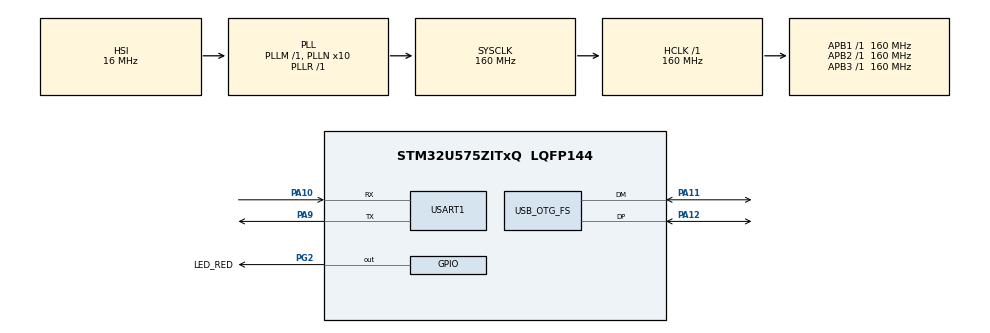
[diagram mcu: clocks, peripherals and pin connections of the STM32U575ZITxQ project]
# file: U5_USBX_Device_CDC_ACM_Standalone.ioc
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CORTEX_M33_NS.userName=CORTEX_M33
GPDMA1.DIRECTION_GPDMACH0=DMA_MEMORY_TO_PERIPH
GPDMA1.IPHANDLE_GPDMACH0-SIMPLEREQUEST_GPDMACH0=__NULL
GPDMA1.REQUEST_GPDMACH0=GPDMA1_REQUEST_USART1_TX
GPDMA1.SRCINC_GPDMACH0=DMA_SINC_INCREMENTED
Mcu.Family=STM32U5
Mcu.Name=STM32U575ZITxQ
Mcu.Package=LQFP144
NVIC.GPDMA1_Channel0_IRQn=true\:0\:0\:false\:false\:true\:false\:true\:true
NVIC.OTG_FS_IRQn=true\:7\:0\:true\:false\:true\:true\:true\:true
NVIC.PriorityGroup=NVIC_PRIORITYGROUP_4
NVIC.USART1_IRQn=true\:6\:0\:true\:false\:true\:false\:true\:true
PA10.GPIO_Speed=GPIO_SPEED_FREQ_HIGH
PA10.Mode=Asynchronous
PA10.Signal=USART1_RX
PA11.GPIO_Speed=GPIO_SPEED_FREQ_HIGH
PA11.Mode=Device_Only
PA11.Signal=USB_OTG_FS_DM
PA12.GPIO_Speed=GPIO_SPEED_FREQ_HIGH
PA12.Mode=Device_Only
PA12.Signal=USB_OTG_FS_DP
PA9.GPIO_Speed=GPIO_SPEED_FREQ_HIGH
PA9.Mode=Asynchronous
PA9.Signal=USART1_TX
PG2.GPIO_Label=LED_RED
PG2.Signal=GPIO_Output
ProjectManager.HeapSize=0x200
ProjectManager.StackSize=0x400
ProjectManager.TargetToolchain=STM32CubeIDE
RCC.ADCFreq_Value=16000000
RCC.AHBFreq_Value=160000000
RCC.APB1Freq_Value=160000000
RCC.APB1TimFreq_Value=160000000
RCC.APB2Freq_Value=160000000
RCC.APB2TimFreq_Value=160000000
RCC.APB3Freq_Value=160000000
RCC.CortexFreq_Value=160000000
RCC.EPOD_VALUE=16000000
RCC.HCLKFreq_Value=160000000
RCC.HSE_VALUE=16000000
RCC.HSI48_VALUE=48000000
RCC.HSI_VALUE=16000000
RCC.LSE_VALUE=32768
RCC.LSIDIV_VALUE=32000
RCC.MSIClockRange=RCC_MSIRANGE_0
RCC.MSI_VALUE=48000000
RCC.PLL1R=1
RCC.PLL2FRACN=0
RCC.PLL3FRACN=0
RCC.PLLFRACN=0
RCC.PLLN=10
RCC.PLLSourceVirtual=RCC_PLLSOURCE_HSI
RCC.SYSCLKFreq_VALUE=160000000
RCC.SYSCLKSource=RCC_SYSCLKSOURCE_PLLCLK
RCC.USBFreq_Value=48000000
RCC.VCOOutputFreq_Value=160000000
USART1.VirtualMode-Asynchronous=VM_ASYNC
USBX.BSP.number=1
USBX.Core_System=1
USBX.USBD_CDCACM_EPINCMD_ADDR=2
USBX.USBD_CDCACM_EPIN_ADDR=1
USBX.USBX_DEVICE_SYS_SIZE=4*1024
USBX.UX_DEVICE_APP_MEM_POOL_SIZE_STANDALONE=1024*8
USBX.UX_DEVICE_CDC_ACM=1
USBX.UX_DEVICE_CLASS_CDC_ACM_TRANSMISSION_DISABLE=1
USBX.UX_Device_Controller=1
USBX.UX_Device_CoreStack=1
USBX.UX_SLAVE_REQUEST_DATA_MAX_LENGTH=512
USBX0.BSP.STBoard=false
USBX0.BSP.api=Unknown
USBX0.BSP.condition=SEMAOoUSBOoOTGOoFSOoDEVICEOoFOROoUSBX & \!DIE455
USBX0.BSP.instance=USB_OTG_FS
USBX0.BSP.ip=USB_OTG_FS
USBX0.BSP.mode=Device_Only
USBX0.BSP.name=USBDevice
USBX0.BSP.solution=USB_OTG_FS
USB_OTG_FS.VirtualMode=Device_Only
VP_GPDMA1_VS_GPDMACH0.Mode=SIMPLEREQUEST_GPDMACH0
VP_ICACHE_VS_ICACHE.Mode=DirectMappedCache
VP_LPBAMQUEUE_VS_QUEUE.Mode=QUEUEMODE
VP_LPBAM_VS_SIG1.Mode=SmartRun
VP_LPBAM_VS_SIG4.Mode=LPDMA1
VP_MEMORYMAP_VS_MEMORYMAP.Mode=CurAppReg
VP_PWR_VS_SECSignals.Mode=Security/Privilege
VP_RCC_USB.Mode=CRS SYNC Source USB
VP_USBX_Core_System.Mode=Core_System
VP_USBX_UX\ Device\ CDC\ ACM\ Class_FS.Mode=UX_Device_class_CDC_ACM_FS
VP_USBX_UX\ Device\ Controller_FS.Mode=UX_Device_Controller_FS
VP_USBX_UX\ Device\ CoreStack_FS.Mode=UX_Device_CoreStack_FS
board=custom

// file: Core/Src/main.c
/* USER CODE BEGIN Header */
/**
  ******************************************************************************
  * @file           : main.c
  * @brief          : Main program body
  ******************************************************************************
  * @attention
  *
  * Copyright (c) 2024 STMicroelectronics.
  * All rights reserved.
  *
  * This software is licensed under terms that can be found in the LICENSE file
  * in the root directory of this software component.
  * If no LICENSE file comes with this software, it is provided AS-IS.
  *
  ******************************************************************************
  */
/* USER CODE END Header */
#include "main.h"
#include "app_usbx_device.h"

UART_HandleTypeDef huart1;
DMA_HandleTypeDef handle_GPDMA1_Channel0;

PCD_HandleTypeDef hpcd_USB_OTG_FS;

void SystemClock_Config(void);
static void MX_GPIO_Init(void);
static void MX_GPDMA1_Init(void);
static void MX_ICACHE_Init(void);
static void MX_USART1_UART_Init(void);
static void MX_USB_OTG_FS_PCD_Init(void);

int main(void)
{

  /* MCU Configuration--------------------------------------------------------*/

  /* Reset of all peripherals, Initializes the Flash interface and the Systick. */
  HAL_Init();

  /* Configure the system clock */
  SystemClock_Config();

  /* Initialize all configured peripherals */
  MX_GPIO_Init();
  MX_GPDMA1_Init();
  MX_ICACHE_Init();
  MX_USART1_UART_Init();
  MX_USB_OTG_FS_PCD_Init();
  MX_USBX_Device_Init();

  /* Infinite loop */
  /* USER CODE BEGIN WHILE */
  while (1)
  {
	  MX_USBX_Device_Process();
    /* USER CODE END WHILE */

  }
}

void SystemClock_Config(void)
{
  RCC_OscInitTypeDef RCC_OscInitStruct = {0};
  RCC_ClkInitTypeDef RCC_ClkInitStruct = {0};
  RCC_CRSInitTypeDef RCC_CRSInitStruct = {0};

  /** Configure the main internal regulator output voltage
  */
  if (HAL_PWREx_ControlVoltageScaling(PWR_REGULATOR_VOLTAGE_SCALE1) != HAL_OK)
  {
    Error_Handler();
  }

  /** Initializes the CPU, AHB and APB buses clocks
  */
  RCC_OscInitStruct.OscillatorType = RCC_OSCILLATORTYPE_HSI48|RCC_OSCILLATORTYPE_HSI;
  RCC_OscInitStruct.HSIState = RCC_HSI_ON;
  RCC_OscInitStruct.HSI48State = RCC_HSI48_ON;
  RCC_OscInitStruct.HSICalibrationValue = RCC_HSICALIBRATION_DEFAULT;
  RCC_OscInitStruct.PLL.PLLState = RCC_PLL_ON;
  RCC_OscInitStruct.PLL.PLLSource = RCC_PLLSOURCE_HSI;
  RCC_OscInitStruct.PLL.PLLMBOOST = RCC_PLLMBOOST_DIV1;
  RCC_OscInitStruct.PLL.PLLM = 1;
  RCC_OscInitStruct.PLL.PLLN = 10;
  RCC_OscInitStruct.PLL.PLLP = 2;
  RCC_OscInitStruct.PLL.PLLQ = 2;
  RCC_OscInitStruct.PLL.PLLR = 1;
  RCC_OscInitStruct.PLL.PLLRGE = RCC_PLLVCIRANGE_1;
  RCC_OscInitStruct.PLL.PLLFRACN = 0;
  if (HAL_RCC_OscConfig(&RCC_OscInitStruct) != HAL_OK)
  {
    Error_Handler();
  }

  /** Initializes the CPU, AHB and APB buses clocks
  */
  RCC_ClkInitStruct.ClockType = RCC_CLOCKTYPE_HCLK|RCC_CLOCKTYPE_SYSCLK
                              |RCC_CLOCKTYPE_PCLK1|RCC_CLOCKTYPE_PCLK2
                              |RCC_CLOCKTYPE_PCLK3;
  RCC_ClkInitStruct.SYSCLKSource = RCC_SYSCLKSOURCE_PLLCLK;
  RCC_ClkInitStruct.AHBCLKDivider = RCC_SYSCLK_DIV1;
  RCC_ClkInitStruct.APB1CLKDivider = RCC_HCLK_DIV1;
  RCC_ClkInitStruct.APB2CLKDivider = RCC_HCLK_DIV1;
  RCC_ClkInitStruct.APB3CLKDivider = RCC_HCLK_DIV1;

  if (HAL_RCC_ClockConfig(&RCC_ClkInitStruct, FLASH_LATENCY_4) != HAL_OK)
  {
    Error_Handler();
  }

  /** Enable the SYSCFG APB clock
  */
  __HAL_RCC_CRS_CLK_ENABLE();

  /** Configures CRS
  */
  RCC_CRSInitStruct.Prescaler = RCC_CRS_SYNC_DIV1;
  RCC_CRSInitStruct.Source = RCC_CRS_SYNC_SOURCE_USB;
  RCC_CRSInitStruct.Polarity = RCC_CRS_SYNC_POLARITY_RISING;
  RCC_CRSInitStruct.ReloadValue = __HAL_RCC_CRS_RELOADVALUE_CALCULATE(48000000,1000);
  RCC_CRSInitStruct.ErrorLimitValue = 34;
  RCC_CRSInitStruct.HSI48CalibrationValue = 32;

  HAL_RCCEx_CRSConfig(&RCC_CRSInitStruct);
}

static void MX_GPDMA1_Init(void)
{

  /* Peripheral clock enable */
  __HAL_RCC_GPDMA1_CLK_ENABLE();

  /* GPDMA1 interrupt Init */
    HAL_NVIC_SetPriority(GPDMA1_Channel0_IRQn, 0, 0);
    HAL_NVIC_EnableIRQ(GPDMA1_Channel0_IRQn);

}

static void MX_ICACHE_Init(void)
{

  /** Enable instruction cache in 1-way (direct mapped cache)
  */
  if (HAL_ICACHE_ConfigAssociativityMode(ICACHE_1WAY) != HAL_OK)
  {
    Error_Handler();
  }
  if (HAL_ICACHE_Enable() != HAL_OK)
  {
    Error_Handler();
  }

}

static void MX_USART1_UART_Init(void)
{

  huart1.Instance = USART1;
  huart1.Init.BaudRate = 115200;
  huart1.Init.WordLength = UART_WORDLENGTH_8B;
  huart1.Init.StopBits = UART_STOPBITS_1;
  huart1.Init.Parity = UART_PARITY_NONE;
  huart1.Init.Mode = UART_MODE_TX_RX;
  huart1.Init.HwFlowCtl = UART_HWCONTROL_NONE;
  huart1.Init.OverSampling = UART_OVERSAMPLING_16;
  huart1.Init.OneBitSampling = UART_ONE_BIT_SAMPLE_DISABLE;
  huart1.Init.ClockPrescaler = UART_PRESCALER_DIV1;
  huart1.AdvancedInit.AdvFeatureInit = UART_ADVFEATURE_NO_INIT;
  if (HAL_UART_Init(&huart1) != HAL_OK)
  {
    Error_Handler();
  }
  if (HAL_UARTEx_SetTxFifoThreshold(&huart1, UART_TXFIFO_THRESHOLD_1_8) != HAL_OK)
  {
    Error_Handler();
  }
  if (HAL_UARTEx_SetRxFifoThreshold(&huart1, UART_RXFIFO_THRESHOLD_1_8) != HAL_OK)
  {
    Error_Handler();
  }
  if (HAL_UARTEx_DisableFifoMode(&huart1) != HAL_OK)
  {
    Error_Handler();
  }

}

static void MX_USB_OTG_FS_PCD_Init(void)
{

  hpcd_USB_OTG_FS.Instance = USB_OTG_FS;
  hpcd_USB_OTG_FS.Init.dev_endpoints = 6;
  hpcd_USB_OTG_FS.Init.speed = PCD_SPEED_FULL;
  hpcd_USB_OTG_FS.Init.phy_itface = PCD_PHY_EMBEDDED;
  hpcd_USB_OTG_FS.Init.Sof_enable = DISABLE;
  hpcd_USB_OTG_FS.Init.low_power_enable = DISABLE;
  hpcd_USB_OTG_FS.Init.lpm_enable = DISABLE;
  hpcd_USB_OTG_FS.Init.battery_charging_enable = DISABLE;
  hpcd_USB_OTG_FS.Init.use_dedicated_ep1 = DISABLE;
  hpcd_USB_OTG_FS.Init.vbus_sensing_enable = DISABLE;
  hpcd_USB_OTG_FS.Init.dma_enable = DISABLE;
  if (HAL_PCD_Init(&hpcd_USB_OTG_FS) != HAL_OK)
  {
    Error_Handler();
  }

}

static void MX_GPIO_Init(void)
{
  GPIO_InitTypeDef GPIO_InitStruct = {0};

  /* GPIO Ports Clock Enable */
  __HAL_RCC_GPIOG_CLK_ENABLE();
  __HAL_RCC_GPIOA_CLK_ENABLE();

  /*Configure GPIO pin Output Level */
  HAL_GPIO_WritePin(LED_RED_GPIO_Port, LED_RED_Pin, GPIO_PIN_RESET);

  /*Configure GPIO pin : LED_RED_Pin */
  GPIO_InitStruct.Pin = LED_RED_Pin;
  GPIO_InitStruct.Mode = GPIO_MODE_OUTPUT_PP;
  GPIO_InitStruct.Pull = GPIO_NOPULL;
  GPIO_InitStruct.Speed = GPIO_SPEED_FREQ_LOW;
  HAL_GPIO_Init(LED_RED_GPIO_Port, &GPIO_InitStruct);

}

void Error_Handler(void)
{
  __disable_irq();
  while (1)
  {
  }
}
